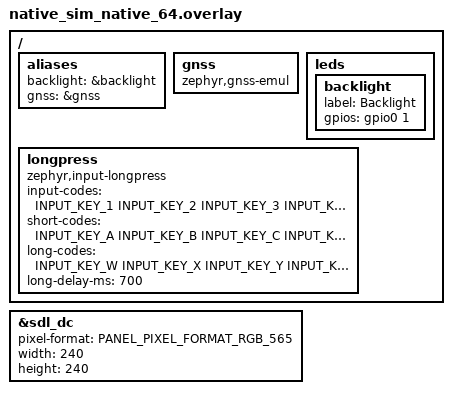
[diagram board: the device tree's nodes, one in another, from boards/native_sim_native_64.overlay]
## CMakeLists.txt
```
cmake_minimum_required(VERSION 3.20.0)

set(BOARD una_watch)
find_package(Zephyr REQUIRED HINTS $ENV{ZEPHYR_BASE})
project(una_zephyr)

target_sources(app PRIVATE
  src/alarm.c
  src/alert.c
  src/baro.c
  src/clock.c
  src/compass.c
  src/compass_page.c
  src/dial.c
  src/draw.c
  src/face.c
  src/fit.c
  src/fonts/font_text_14.c
  src/fonts/font_text_20.c
  src/gnss.c
  src/hr.c
  src/hr_alg.c
  src/hr_page.c
  src/main.c
  src/messages.c
  src/motion.c
  src/pairing.c
  src/phone.c
  src/record.c
  src/record_page.c
  src/screenshot.c
  src/settings.c
  src/stopwatch.c
  src/systems.c
  src/timer.c
  src/totp.c
  src/totp_page.c
  src/ui.c
)

# The hardware, or the simulator's stand-ins for it (-b native_sim/native/64).
if(CONFIG_BOARD_UNA_WATCH)
  target_sources(app PRIVATE
    src/alert_hw.c
    src/baro_hw.c
    src/compass_hw.c
    src/hr_hw.c
    src/motion_hw.c
    src/power.c
    src/storage.c
    src/usb.c
    src/watchdog.c
  )
  # The radio, or in its place what loads the radio chip's firmware
  # (-DEXTRA_CONF_FILE=bnrg-update.conf).
  if(CONFIG_UNA_BNRG_UPDATE)
    get_filename_component(bnrg_fw ${CONFIG_UNA_BNRG_FW} ABSOLUTE BASE_DIR ${CMAKE_SOURCE_DIR})
    if(NOT EXISTS ${bnrg_fw})
      message(FATAL_ERROR "CONFIG_UNA_BNRG_FW: there is no ${bnrg_fw}")
    endif()
    generate_inc_file_for_target(app ${bnrg_fw}
      ${ZEPHYR_BINARY_DIR}/include/generated/bnrg_fw.inc)
    target_sources(app PRIVATE src/bluenrg.c src/bnrg_update.c)
  else()
    target_sources(app PRIVATE src/bluetooth.c)
  endif()
  # PixArt's library on the heart-rate sensor (-DEXTRA_CONF_FILE=hr-ref.conf).
  if(CONFIG_UNA_PIXART_REF)
    get_filename_component(pixart ${CONFIG_UNA_PIXART_DIR} ABSOLUTE BASE_DIR ${CMAKE_SOURCE_DIR})
    if(NOT EXISTS ${pixart}/lib/libuna_vendor.a)
      message(FATAL_ERROR "CONFIG_UNA_PIXART_DIR: there is no ${pixart}/lib/libuna_vendor.a")
    endif()
    target_sources(app PRIVATE src/hr_ref.c)
    target_include_directories(app PRIVATE ${pixart}/include/pixart ${pixart}/include/pixart/alg)
    target_link_libraries(app PRIVATE ${pixart}/lib/libuna_vendor.a)
  endif()
else()
  target_sources(app PRIVATE src/sim.c)
endif()
```

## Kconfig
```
config UNA_BNRG_UPDATE
	bool "Load the radio chip's firmware instead of running the radio"
	depends on BOARD_UNA_WATCH
	help
	  Builds the watch without Bluetooth and with ST's firmware image for
	  the BlueNRG-2N inside, which the shell command "bnrg update" writes
	  into the chip. See bnrg-update.conf.

config UNA_BNRG_FW
	string "ST's firmware image for the radio chip"
	depends on UNA_BNRG_UPDATE
	default "../../../firmware/ble/BlueNRG_2N_FW_V3_4_0.bin"
	help
	  BlueNRG_2N_FW_V3_4_0.bin from fw_images/ in ST's STSW-BNRG2N, by its
	  path from the application's folder or in full.

config UNA_HR_RAW_RECORDED
	bool "Keep the heart-rate sensor's samples of every recording"
	default y
	help
	  While an activity is recorded, what the sensor and the accelerometer
	  gave is written to /USER:/Log/PPG/ as "hr raw on" writes it, about
	  1 MB an hour, for scripts/hr-replay: the pulse while running is not
	  right yet, and this is what there is to work on it with. To be turned
	  off when it is.

config UNA_PIXART_REF
	bool "PixArt's closed library on the heart-rate sensor, with the bus traced"
	depends on BOARD_UNA_WATCH && FPU && FP_HARDABI
	help
	  For working out the PAH8316's registers and for a pulse to hold our
	  own against: the shell command "hrref" runs PixArt's driver and
	  algorithm and writes what they do to /USER:/Log/PPG/. The library is
	  PixArt's and not ours to pass on; it is linked from where
	  UNA_PIXART_DIR says and never copied. See hr-ref.conf.

config UNA_PIXART_DIR
	string "The stock kernel's VendorLib folder"
	depends on UNA_PIXART_REF
	default "../../../refs/una-kernel-public/Software/ThirdParty/VendorLib"
	help
	  The folder with lib/libuna_vendor.a and include/pixart/, by its path
	  from the application's folder or in full.

source "Kconfig.zephyr"
```

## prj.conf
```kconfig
# What the watch and the simulator (native_sim) share. The watch's hardware
# is configured in boards/una_watch.conf, the simulator in
# boards/native_sim_native_64.conf.

CONFIG_GPIO=y
CONFIG_INPUT=y
CONFIG_REBOOT=y
CONFIG_MAIN_STACK_SIZE=8192
# The UI must not be able to starve the shell: a frame is 35 ms of busy work.
CONFIG_MAIN_THREAD_PRIORITY=10
CONFIG_SHELL_THREAD_PRIORITY_OVERRIDE=y
CONFIG_SHELL_THREAD_PRIORITY=5

# Display and UI
CONFIG_DISPLAY=y
CONFIG_LVGL=y
CONFIG_LV_Z_MEM_POOL_SIZE=65536
CONFIG_LV_COLOR_DEPTH_16=y
# One full frame per flush: the panel is always rewritten whole.
CONFIG_LV_Z_VDB_SIZE=100
CONFIG_LV_Z_FULL_REFRESH=y
CONFIG_LV_Z_SHELL=y
CONFIG_LV_FONT_MONTSERRAT_12=y
CONFIG_LV_FONT_MONTSERRAT_14=y
CONFIG_LV_FONT_MONTSERRAT_20=y
CONFIG_LV_FONT_MONTSERRAT_48=y

# Shell
CONFIG_LOG=y
CONFIG_LOG_CMDS=y
CONFIG_SHELL=y
CONFIG_SHELL_PROMPT_UART="una:~$ "
CONFIG_SHELL_VT100_COLORS=n
CONFIG_SHELL_STACK_SIZE=6144
CONFIG_KERNEL_SHELL=y
CONFIG_DEVICE_SHELL=y
CONFIG_GPIO_SHELL=y
CONFIG_INPUT_SHELL=y
CONFIG_THREAD_NAME=y
CONFIG_THREAD_STACK_INFO=y
CONFIG_BASE64=y

CONFIG_RTC=y
CONFIG_RTC_SHELL=y

# Settings in internal flash (storage partition)
CONFIG_FLASH=y
CONFIG_FLASH_MAP=y
CONFIG_SETTINGS=y
CONFIG_SETTINGS_RUNTIME=y
CONFIG_ZMS=y
CONFIG_SETTINGS_ZMS=y

# The recorder: FIT files on the user volume
CONFIG_FILE_SYSTEM=y
CONFIG_CRC=y
```

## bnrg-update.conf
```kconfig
# The watch as a tool that loads the radio chip's firmware: no Bluetooth, and
# the shell commands "bnrg info" and "bnrg update" (src/bnrg_update.c).
#
#   west build -b una_watch --sysbuild -d build/bnrg zephyr/una/app -- \
#     -DEXTRA_CONF_FILE=bnrg-update.conf
#
# The image is ST's (STSW-BNRG2N, fw_images/BlueNRG_2N_FW_V3_4_0.bin in the
# zip) and not ours to pass on, so it is not in the repository. It is looked
# for in firmware/ble/; CONFIG_UNA_BNRG_FW says where else.
CONFIG_BT=n
CONFIG_UNA_BNRG_UPDATE=y
```

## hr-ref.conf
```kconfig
# The watch with PixArt's closed library on the heart-rate sensor, and the
# shell command "hrref" (src/hr_ref.c): what the library does on the bus is
# written to /USER:/Log/PPG/, with the samples and the pulse it makes of them.
#
#   west build -b una_watch --sysbuild -d build/hrref zephyr/una/app -- \
#     -DEXTRA_CONF_FILE=hr-ref.conf
#
# The library is PixArt's, passed on by UNA as a binary, and is not in the
# repository. It is looked for in the stock kernel under refs/;
# CONFIG_UNA_PIXART_DIR says where else.
CONFIG_UNA_PIXART_REF=y
# The library passes floats in the FPU's registers, so all of the watch must.
CONFIG_FPU=y
CONFIG_FP_HARDABI=y
CONFIG_FPU_SHARING=y
# And it wants the mathematics and qsort of a full C library.
CONFIG_NEWLIB_LIBC=y
# That library has an initializer of its own to be run at boot.
CONFIG_STATIC_INIT_GNU=y
```

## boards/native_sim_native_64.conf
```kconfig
# The simulator: the UI and shell as a Linux program. See src/sim.c.

# Works without a GPU and with SDL_VIDEODRIVER=dummy (no window).
CONFIG_SDL_DISPLAY_USE_HARDWARE_ACCELERATOR=n

# The watch has no touch screen. LVGL would poll one 30 times a second.
CONFIG_LV_Z_POINTER_FROM_CHOSEN_TOUCH=n

# The user volume is a directory of the computer: -volume=<dir>:/USER
CONFIG_FILE_SYSTEM_NATIVE_MOUNT=y
CONFIG_FILE_SYSTEM_SHELL=y

# An emulated GNSS receiver, moved about with "sim gps" and "sim move"
CONFIG_GNSS=y
CONFIG_GNSS_SATELLITES=y
CONFIG_GNSS_EMUL_MANUAL_UPDATE=y
CONFIG_PM_DEVICE=y
CONFIG_SHELL_CMD_BUFF_SIZE=3072
```

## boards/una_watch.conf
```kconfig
# The watch itself: its hardware, storage, Bluetooth and firmware update.

CONFIG_HWINFO=y
CONFIG_LOG_BUFFER_SIZE=16384
CONFIG_WATCHDOG=y

# Both serial ports are set up in src/usb.c; the board default does only one.
CONFIG_CDC_ACM_SERIAL_INITIALIZE_AT_BOOT=n

# Shell on the first USB serial port
CONFIG_SHELL_BACKEND_SERIAL_CHECK_DTR=y
CONFIG_HWINFO_SHELL=y
CONFIG_DEVMEM_SHELL=y

# mcumgr on the second USB serial port: upload a new image, test it, reset
CONFIG_STREAM_FLASH=y
CONFIG_IMG_MANAGER=y
CONFIG_ZCBOR=y
CONFIG_NET_BUF=y
CONFIG_CRC=y
CONFIG_MCUMGR=y
CONFIG_UART_MCUMGR=y
CONFIG_MCUMGR_TRANSPORT_UART=y
CONFIG_MCUMGR_GRP_IMG=y
CONFIG_MCUMGR_GRP_OS=y
CONFIG_MCUBOOT_SHELL=y
CONFIG_MCUMGR_GRP_OS_BOOTLOADER_INFO=y
CONFIG_MCUMGR_GRP_OS_INFO=y
CONFIG_UART_INTERRUPT_DRIVEN=y

# Bluetooth: Zephyr's host, with the BlueNRG-2N as a plain controller (ST's
# firmware 3.4.0 or later in it: see bnrg-update.conf). The chip takes ST's
# commands for its address, counts no packets back to the host and knows
# nothing of Zephyr's vendor commands.
CONFIG_SPI=y
CONFIG_BT=y
CONFIG_BT_PERIPHERAL=y
CONFIG_BT_BLUENRG_ACI=y
CONFIG_BT_HCI_ACL_FLOW_CONTROL=n
CONFIG_BT_HCI_VS=n
CONFIG_BT_DEVICE_NAME="UNA Watch"
CONFIG_BT_DEVICE_APPEARANCE=192
# The serial line to the phone: src/bluetooth.c has its own instance of the
# service, for a paired phone only
CONFIG_BT_ZEPHYR_NUS=y
CONFIG_BT_ZEPHYR_NUS_DEFAULT_INSTANCE=n
# Pairing: LE Secure Connections only, by the passkey the watch shows. The
# bonds are kept in settings; a fifth phone takes the place of the oldest.
CONFIG_BT_SMP=y
# No database hash for a phone to keep the services by. With it, Android
# connects, encrypts, and then asks nothing more: Gadgetbridge waits for ever
# (tried again on 23 Nov, with the same phone and bond: stuck with it, well
# without). The price: a paired phone is not told when the services change,
# so the serial service keeps its place (see src/bluetooth.c) and what is
# added after it is found by a phone only when it pairs anew.
CONFIG_BT_GATT_CACHING=n
# Battery level and what the device is, in the standard way, for any app
CONFIG_BT_BAS=y
CONFIG_BT_DIS=y
CONFIG_BT_DIS_MODEL_NUMBER_STR="UNA Watch"
CONFIG_BT_DIS_MANUF_NAME_STR="Una Watch Ltd"
CONFIG_BT_DIS_PNP=n
# The pulse in the standard way too: the sensor is on while an app listens
CONFIG_BT_HRS=y
CONFIG_BT_HCI_ERR_TO_STR=y
CONFIG_BT_SECURITY_ERR_TO_STR=y
CONFIG_BT_SMP_SC_PAIR_ONLY=y
CONFIG_BT_SETTINGS=y
CONFIG_BT_MAX_PAIRED=4
CONFIG_BT_KEYS_OVERWRITE_OLDEST=y
# Its keys are made of the SoC's random numbers (&rng); the host's
# cryptography (PSA) allocates.
CONFIG_ENTROPY_GENERATOR=y
# Pairing was seen to leave the stack's receiving thread 100 bytes of 1200.
CONFIG_BT_RX_STACK_SIZE=2048
CONFIG_COMMON_LIBC_MALLOC_ARENA_SIZE=32768
# As long a packet as the chip carries in one piece
CONFIG_BT_L2CAP_TX_MTU=247
CONFIG_BT_BUF_ACL_TX_SIZE=251
CONFIG_BT_BUF_ACL_RX_SIZE=251
# As many as the chip says it holds
CONFIG_BT_BUF_ACL_TX_COUNT=7
# The pace the watch would like, asked for by src/bluetooth.c once the phone
# has opened the line and not by the stack some seconds into any connection:
# 100 to 200 ms, of which four in five may be skipped, lost after 6 s.
CONFIG_BT_GAP_AUTO_UPDATE_CONN_PARAMS=n
CONFIG_BT_PERIPHERAL_PREF_MIN_INT=80
CONFIG_BT_PERIPHERAL_PREF_MAX_INT=160
CONFIG_BT_PERIPHERAL_PREF_LATENCY=4
CONFIG_BT_PERIPHERAL_PREF_TIMEOUT=600

CONFIG_I2C=y
CONFIG_I2C_SHELL=y
CONFIG_SENSOR=y
CONFIG_PWM=y

# Stop 2 whenever nothing runs and USB is off
CONFIG_PM=y
CONFIG_STATS=y
CONFIG_STATS_NAMES=y
CONFIG_STATS_SHELL=y
CONFIG_PM_STATS=y
CONFIG_GPIO_HOGS=y

# Storage: eMMC, the stock user volume (exFAT) at /USER:
CONFIG_DISK_ACCESS=y
CONFIG_SDMMC_STM32_EMMC=y
CONFIG_FILE_SYSTEM=y
CONFIG_FAT_FILESYSTEM_ELM=y
CONFIG_FS_FATFS_EXFAT=y
CONFIG_FS_FATFS_CUSTOM_MOUNT_POINT_COUNT=1
CONFIG_FS_FATFS_CUSTOM_MOUNT_POINTS="USER"
CONFIG_FS_FATFS_MOUNT_MKFS=n
CONFIG_FILE_SYSTEM_SHELL=y
CONFIG_MCUMGR_GRP_FS=y
CONFIG_MCUMGR_GRP_FS_MAX_FILE_SIZE_4GB=y

# Telemetry: the log, kept on the eMMC by Zephyr's file-system log backend.
# 32 files of 1 MB, oldest overwritten.
CONFIG_LOG_BACKEND_FS=y
# Several threads use the volume (log, shell, mcumgr). Re-entrancy needs the
# long-file-name buffer on the caller's stack, hence the larger stacks.
CONFIG_FS_FATFS_REENTRANT=y
CONFIG_FS_FATFS_LFN_MODE_STACK=y
CONFIG_LOG_PROCESS_THREAD_STACK_SIZE=4096
CONFIG_MCUMGR_TRANSPORT_WORKQUEUE_STACK_SIZE=8192
CONFIG_SYSTEM_WORKQUEUE_STACK_SIZE=4096
CONFIG_LOG_BACKEND_FS_DIR="/USER:/Log/Zephyr"
CONFIG_LOG_BACKEND_FS_FILE_PREFIX="log."
CONFIG_LOG_BACKEND_FS_FILE_SIZE=1048576
CONFIG_LOG_BACKEND_FS_FILES_LIMIT=32
CONFIG_THREAD_RUNTIME_STATS=y
CONFIG_SCHED_THREAD_USAGE=y
CONFIG_SCHED_THREAD_USAGE_ALL=y

# GNSS: the Airoha receiver, off until the recorder asks for it
CONFIG_GNSS=y
CONFIG_GNSS_SATELLITES=y
```

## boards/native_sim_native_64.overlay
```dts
/*
 * The simulator: the watch's 240x240 screen in the SDL display, the
 * backlight on an emulated pin, the same button codes as the watch.
 */

#include <zephyr/dt-bindings/display/panel.h>
#include <zephyr/dt-bindings/input/input-event-codes.h>

/ {
	aliases {
		backlight = &backlight;
		gnss = &gnss;
	};

	gnss: gnss {
		compatible = "zephyr,gnss-emul";
	};

	leds {
		backlight: backlight {
			label = "Backlight";
			gpios = <&gpio0 1 GPIO_ACTIVE_HIGH>;
		};
	};

	/* As in una_watch.dts. There are no buttons: "input report" presses them. */
	longpress {
		compatible = "zephyr,input-longpress";
		input-codes = <INPUT_KEY_1 INPUT_KEY_2 INPUT_KEY_3 INPUT_KEY_4>;
		short-codes = <INPUT_KEY_A INPUT_KEY_B INPUT_KEY_C INPUT_KEY_D>;
		long-codes = <INPUT_KEY_W INPUT_KEY_X INPUT_KEY_Y INPUT_KEY_Z>;
		long-delay-ms = <700>;
	};
};

&sdl_dc {
	pixel-format = <PANEL_PIXEL_FORMAT_RGB_565>;
	width = <240>;
	height = <240>;
};
```

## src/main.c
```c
/*
 * Zephyr on the UNA Watch: the UI in the main thread, a shell on the USB
 * serial port and mcumgr for loading the next build.
 */

#include "ui.h"

int main(void)
{
	ui_run();
	return 0;
}
```

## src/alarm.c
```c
/*
 * One daily alarm.
 */

#include <zephyr/init.h>
#include <zephyr/kernel.h>
#include <zephyr/settings/settings.h>

#include "alarm.h"
#include "alert.h"
#include "clock.h"
#include "ui.h"

#define RING_S 60

static struct {
	uint8_t hour;
	uint8_t minute;
	uint8_t on;
} alarm = {.hour = 7};

bool alarm_get(int *hour, int *minute)
{
	*hour = alarm.hour;
	*minute = alarm.minute;
	return alarm.on;
}

static void check(struct k_work *work);
static K_WORK_DELAYABLE_DEFINE(check_work, check);

/*
 * Looks at the clock at the alarm's minute, and at least once an hour on the
 * way there, so that a wait of many hours does not drift off the RTC.
 */
static void schedule(void)
{
	struct tm now;
	int wait_s = 60;

	if (!alarm.on) {
		k_work_cancel_delayable(&check_work);
		return;
	}
	if (clock_local(&now)) {
		wait_s = (alarm.hour * 60 + alarm.minute - now.tm_hour * 60 - now.tm_min) * 60 -
			 now.tm_sec;
		if (wait_s <= 0) {
			wait_s += 24 * 3600;
		}
	}
	k_work_reschedule(&check_work, K_SECONDS(MIN(wait_s, 3600)));
}

static void check(struct k_work *work)
{
	struct tm now;

	ARG_UNUSED(work);

	if (alarm.on && clock_local(&now) && now.tm_hour == alarm.hour &&
	    now.tm_min == alarm.minute) {
		alert_ring("Alarm", RING_S);
	}
	schedule();
}

void alarm_clock_changed(void)
{
	schedule();
}

static int alarm_setting_set(const char *name, size_t len, settings_read_cb read_cb, void *cb_arg)
{
	if (settings_name_steq(name, "daily", NULL) && len == sizeof(alarm)) {
		return read_cb(cb_arg, &alarm, sizeof(alarm)) < 0 ? -EIO : 0;
	}
	return -ENOENT;
}
SETTINGS_STATIC_HANDLER_DEFINE(alarm, "alarm", NULL, alarm_setting_set, NULL, NULL);

/* After clock_init, which loads the settings. */
static int alarm_init(void)
{
	schedule();
	return 0;
}
SYS_INIT(alarm_init, APPLICATION, 97);

/*
 * The page: SELECT turns the alarm on and off; held, it goes in to set the
 * hour, then the minute.
 */

enum field {
	FIELD_NONE, /* not inside */
	FIELD_HOUR,
	FIELD_MINUTE,
};

static enum field field;
static lv_obj_t *hour_label;
static lv_obj_t *colon_label;
static lv_obj_t *minute_label;
static lv_obj_t *on_label;
static lv_obj_t *hint_label;

static void alarm_enter(void)
{
	ui_title("ALARM");
	hour_label = ui_label(&lv_font_montserrat_48, 0xffffff, -14);
	lv_obj_align(hour_label, LV_ALIGN_CENTER, -40, -14);
	colon_label = ui_label(&lv_font_montserrat_48, 0xffffff, -18);
	lv_label_set_text(colon_label, ":");
	minute_label = ui_label(&lv_font_montserrat_48, 0xffffff, -14);
	lv_obj_align(minute_label, LV_ALIGN_CENTER, 40, -14);
	on_label = ui_label(&lv_font_montserrat_20, 0xffffff, 32);
	hint_label = ui_label(&lv_font_montserrat_14, 0xaaaaaa, 72);
	field = FIELD_NONE;
}

static uint32_t alarm_update(void)
{
	/* An alarm that is off is grey; the field being set is cyan. */
	const lv_color_t plain = lv_color_hex(alarm.on ? 0xffffff : 0x555555);
	const lv_color_t chosen = lv_color_hex(0x00ffff);

	lv_label_set_text_fmt(hour_label, "%02d", alarm.hour);
	lv_label_set_text_fmt(minute_label, "%02d", alarm.minute);
	lv_label_set_text(on_label, alarm.on ? "ON" : "OFF");
	lv_obj_set_style_text_color(on_label, lv_color_hex(alarm.on ? 0x00ff00 : 0x555555), 0);
	lv_obj_set_style_text_color(colon_label, plain, 0);
	lv_obj_set_style_text_color(hour_label, field == FIELD_HOUR ? chosen : plain, 0);
	lv_obj_set_style_text_color(minute_label, field == FIELD_MINUTE ? chosen : plain, 0);
	lv_label_set_text(hint_label, field == FIELD_NONE ? "hold: set" : "");
	return UINT32_MAX;
}

static bool alarm_key(enum ui_key key, bool held)
{
	int dir = key == UI_KEY_UP ? 1 : -1;

	if (field == FIELD_NONE) {
		if (key != UI_KEY_SELECT) {
			return false;
		}
		if (held) {
			field = FIELD_HOUR;
			return true;
		}
		alarm.on = !alarm.on;
	} else if (key == UI_KEY_SELECT || key == UI_KEY_BACK) {
		if (!held) {
			field = key == UI_KEY_SELECT && field == FIELD_HOUR ? FIELD_MINUTE
									     : FIELD_NONE;
		}
		return true;
	} else if (field == FIELD_HOUR) {
		alarm.hour = (alarm.hour + 24 + dir) % 24;
	} else if (held) {
		/* Fives, to the next multiple; held: single minutes. */
		alarm.minute = (alarm.minute + 60 + dir) % 60;
	} else if (dir > 0) {
		alarm.minute = (alarm.minute / 5 * 5 + 5) % 60;
	} else {
		alarm.minute = ((alarm.minute + 4) / 5 * 5 + 55) % 60;
	}
	settings_save_one("alarm/daily", &alarm, sizeof(alarm));
	schedule();
	return true;
}

const struct ui_screen alarm_screen = {
	.name = "alarm",
	.enter = alarm_enter,
	.update = alarm_update,
	.key = alarm_key,
};
```

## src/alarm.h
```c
#ifndef UNA_ALARM_H_
#define UNA_ALARM_H_

#include <stdbool.h>

/* The daily alarm's time; false when it is off. */
bool alarm_get(int *hour, int *minute);

/* The clock was set: work out again when the alarm is due. */
void alarm_clock_changed(void);

#endif
```

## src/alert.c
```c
/*
 * Alerts: a beep-and-buzz pattern, and the screen shown while it plays.
 */

#include <stdlib.h>

#include <zephyr/kernel.h>
#include <zephyr/logging/log.h>
#include <zephyr/settings/settings.h>
#include <zephyr/shell/shell.h>

#include "alert.h"
#include "clock.h"
#include "ui.h"

LOG_MODULE_REGISTER(alert, LOG_LEVEL_INF);

/* Two short pulses a second. */
static const struct {
	uint16_t ms;
	bool on;
} pattern[] = {{150, true}, {100, false}, {150, true}, {600, false}};

#define PATTERN_MS 1000

static uint8_t sound = 1;
static uint8_t vibration = 1;

/*
 * A pattern is asked for from any thread and played by the work alone: the
 * steps to play from the beginning, 0 to stop, -1 when nothing is asked.
 * Cancelling the work instead would, if it is running just then, have the
 * kernel refuse every schedule until it returns, its own for the next step
 * among them, and whatever was on would stay on.
 */
static atomic_t asked = ATOMIC_INIT(-1);

/* The work's own: steps still to play, the one that is next, and when. */
static int steps_left;
static int step;
static int64_t step_at;

static void play_step(struct k_work *work);
static K_WORK_DELAYABLE_DEFINE(step_work, play_step);

static void play_step(struct k_work *work)
{
	int fresh = atomic_set(&asked, -1);
	int64_t now = k_uptime_get();
	bool on;

	if (fresh >= 0) {
		steps_left = fresh;
		step = 0;
	} else if (steps_left > 0 && now < step_at) {
		/* Woken for a pattern that an earlier run already took. */
		k_work_schedule(&step_work, K_MSEC(step_at - now));
		return;
	}
	if (steps_left <= 0) {
		buzzer_set(false);
		motor_set(false);
		return;
	}
	steps_left--;
	on = pattern[step].on;
	buzzer_set(on && sound);
	motor_set(on && vibration);
	step_at = k_uptime_get() + pattern[step].ms;
	k_work_schedule(&step_work, K_MSEC(pattern[step].ms));
	step = (step + 1) % ARRAY_SIZE(pattern);
}

/* Whether what was last asked for is the ring that the ring screen shows. */
static atomic_t ringing;

static void start(int steps)
{
	atomic_set(&ringing, 0);
	atomic_set(&asked, steps);
	k_work_reschedule(&step_work, K_NO_WAIT);
}

void alert_stop(void)
{
	start(0);
}

void alert_blip(void)
{
	start(2);
}

/* The screen */

static const char *ring_title;
static char ring_time[6];

static void ring_enter(void)
{
	lv_label_set_text(ui_label(&lv_font_montserrat_48, 0xffffff, -20), ring_time);
	lv_label_set_text(ui_label(&font_text_20, 0xffff00, 30), ring_title);
	lv_label_set_text(ui_label(&lv_font_montserrat_14, 0xaaaaaa, 76), "any button: dismiss");
}

static uint32_t ring_update(void)
{
	return UINT32_MAX;
}

static bool ring_key(enum ui_key key, bool held)
{
	ARG_UNUSED(key);
	ARG_UNUSED(held);

	ui_pop();
	return true;
}

/*
 * Leaving is what silences it, so that holding BACK, which the screen does
 * not see, does too. A blip that has come since is left alone.
 */
static void ring_leave(void)
{
	if (atomic_get(&ringing)) {
		alert_stop();
	}
}

static const struct ui_screen ring_screen = {
	.name = "ring",
	.enter = ring_enter,
	.update = ring_update,
	.key = ring_key,
	.leave = ring_leave,
};

void alert_ring(const char *title, int seconds)
{
	struct tm now;

	LOG_INF("ring: %s", title);
	ring_title = title;
	if (clock_local(&now)) {
		snprintk(ring_time, sizeof(ring_time), "%02d:%02d", now.tm_hour, now.tm_min);
	} else {
		ring_time[0] = '\0';
	}
	start(seconds * 1000 / PATTERN_MS * ARRAY_SIZE(pattern));
	atomic_set(&ringing, 1);
	ui_show(&ring_screen);
}

/* Settings */

bool alert_sound(void)
{
	return sound;
}

void alert_set_sound(bool on)
{
	sound = on;
	settings_save_one("alert/sound", &sound, sizeof(sound));
}

bool alert_vibration(void)
{
	return vibration;
}

void alert_set_vibration(bool on)
{
	vibration = on;
	settings_save_one("alert/vibration", &vibration, sizeof(vibration));
}

static int alert_setting_set(const char *name, size_t len, settings_read_cb read_cb, void *cb_arg)
{
	uint8_t *value = settings_name_steq(name, "sound", NULL)       ? &sound
			 : settings_name_steq(name, "vibration", NULL) ? &vibration
								       : NULL;

	if (value == NULL || len != sizeof(*value)) {
		return -ENOENT;
	}
	return read_cb(cb_arg, value, sizeof(*value)) < 0 ? -EIO : 0;
}
SETTINGS_STATIC_HANDLER_DEFINE(alert, "alert", NULL, alert_setting_set, NULL, NULL);

/* alert ring [seconds] | alert stop */
static int cmd_ring(const struct shell *sh, size_t argc, char **argv)
{
	alert_ring("Test", argc > 1 ? atoi(argv[1]) : 5);
	return 0;
}

static int cmd_stop(const struct shell *sh, size_t argc, char **argv)
{
	alert_stop();
	return 0;
}

SHELL_STATIC_SUBCMD_SET_CREATE(alert_cmds,
	SHELL_CMD_ARG(ring, NULL, "Ring for [seconds] (default 5)", cmd_ring, 1, 1),
	SHELL_CMD(stop, NULL, "Silence", cmd_stop),
	SHELL_SUBCMD_SET_END);
SHELL_CMD_REGISTER(alert, &alert_cmds, "Beep and vibrate", NULL);
```

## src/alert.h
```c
#ifndef UNA_ALERT_H_
#define UNA_ALERT_H_

#include <stdbool.h>

/*
 * Beep and vibrate for up to `seconds`, and show `title` until a button is
 * pressed, which also ends the noise. From any thread.
 */
void alert_ring(const char *title, int seconds);
void alert_stop(void);

/* One short beep and buzz. */
void alert_blip(void);

/* What an alert may use. Stored. */
bool alert_sound(void);
void alert_set_sound(bool on);
bool alert_vibration(void);
void alert_set_vibration(bool on);

/* The hardware: src/alert_hw.c on the watch, src/sim.c in the simulator. */
void buzzer_set(bool on);
void motor_set(bool on);

#endif
```

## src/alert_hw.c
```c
/*
 * The buzzer and the vibration motor.
 *
 * Buzzer: a piezo on TIM4 channel 3 behind two enable pins that set its
 * level, as in Components/Buzzer.cpp of una-kernel-public. Motor: an ERM on a
 * DRV2625, driven open-loop in real-time mode, which needs none of the
 * calibration the stock firmware runs; the chip is in shutdown otherwise.
 */

#include <zephyr/device.h>
#include <zephyr/drivers/gpio.h>
#include <zephyr/drivers/i2c.h>
#include <zephyr/drivers/pwm.h>
#include <zephyr/init.h>
#include <zephyr/kernel.h>
#include <zephyr/logging/log.h>
#include <zephyr/pm/policy.h>

#include "alert.h"

LOG_MODULE_REGISTER(alert_hw, LOG_LEVEL_INF);

#define USER DT_PATH(zephyr_user)

static const struct pwm_dt_spec buzzer = PWM_DT_SPEC_GET(USER);
static const struct gpio_dt_spec buzzer_en1 = GPIO_DT_SPEC_GET_BY_IDX(USER, buzzer_en_gpios, 0);
static const struct gpio_dt_spec buzzer_en2 = GPIO_DT_SPEC_GET_BY_IDX(USER, buzzer_en_gpios, 1);
static const struct gpio_dt_spec motor_en = GPIO_DT_SPEC_GET(USER, haptic_enable_gpios);
static const struct device *const i2c = DEVICE_DT_GET(DT_NODELABEL(i2c1));

#define DRV2625_ADDR 0x5a

#define DRV2625_MODE      0x07 /* [1:0] mode, 0 = real-time; [3:2] trigger pin */
#define DRV2625_LOOP      0x08
#define DRV2625_GO        0x0c
#define DRV2625_RTP_INPUT 0x0e
#define DRV2625_OD_CLAMP  0x20

/* ERM, open loop, brake into standby when stopped. */
#define DRV2625_LOOP_ERM_OPEN (BIT(6) | BIT(3))
/* 2.95 V, the stock firmware's limit for this motor. */
#define DRV2625_OD_CLAMP_2V95 137

void buzzer_set(bool on)
{
	static bool is_on;

	if (on == is_on) {
		return;
	}
	is_on = on;
	if (on) {
		/* The timer stands still in Stop mode. */
		pm_policy_state_lock_get(PM_STATE_SUSPEND_TO_IDLE, PM_ALL_SUBSTATES);
		/* Both enables: the loudest of the three levels. */
		gpio_pin_set_dt(&buzzer_en1, 1);
		gpio_pin_set_dt(&buzzer_en2, 1);
		pwm_set_pulse_dt(&buzzer, buzzer.period / 2);
	} else {
		pwm_set_pulse_dt(&buzzer, 0);
		gpio_pin_set_dt(&buzzer_en1, 0);
		gpio_pin_set_dt(&buzzer_en2, 0);
		pm_policy_state_lock_put(PM_STATE_SUSPEND_TO_IDLE, PM_ALL_SUBSTATES);
	}
}

void motor_set(bool on)
{
	static bool is_on;
	int err;

	if (on == is_on) {
		return;
	}
	is_on = on;
	if (!on) {
		i2c_reg_write_byte(i2c, DRV2625_ADDR, DRV2625_GO, 0);
		gpio_pin_set_dt(&motor_en, 0);
		return;
	}
	/* Out of shutdown the registers are at their defaults. */
	gpio_pin_set_dt(&motor_en, 1);
	k_msleep(2);
	err = i2c_reg_write_byte(i2c, DRV2625_ADDR, DRV2625_LOOP, DRV2625_LOOP_ERM_OPEN);
	if (err == 0) {
		err = i2c_reg_write_byte(i2c, DRV2625_ADDR, DRV2625_OD_CLAMP,
					 DRV2625_OD_CLAMP_2V95);
	}
	if (err == 0) {
		err = i2c_reg_update_byte(i2c, DRV2625_ADDR, DRV2625_MODE, 0x0f, 0);
	}
	if (err == 0) {
		err = i2c_reg_write_byte(i2c, DRV2625_ADDR, DRV2625_RTP_INPUT, 0x7f);
	}
	if (err == 0) {
		err = i2c_reg_write_byte(i2c, DRV2625_ADDR, DRV2625_GO, 1);
	}
	if (err != 0) {
		LOG_ERR("motor driver: %d", err);
	}
}

static int alert_hw_init(void)
{
	gpio_pin_configure_dt(&buzzer_en1, GPIO_OUTPUT_INACTIVE);
	gpio_pin_configure_dt(&buzzer_en2, GPIO_OUTPUT_INACTIVE);
	gpio_pin_configure_dt(&motor_en, GPIO_OUTPUT_INACTIVE);
	return 0;
}
SYS_INIT(alert_hw_init, APPLICATION, CONFIG_APPLICATION_INIT_PRIORITY);
```

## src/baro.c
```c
/*
 * The barometer, for height gained and lost: powered while anyone wants it,
 * read once a second, the readings evened out.
 */

#include <errno.h>
#include <stdlib.h>
#include <string.h>

#include <zephyr/kernel.h>
#include <zephyr/logging/log.h>
#include <zephyr/shell/shell.h>
#include <zephyr/sys/atomic.h>

#include "baro.h"
#include "ui.h"

LOG_MODULE_REGISTER(baro, LOG_LEVEL_INF);

#define PERIOD_MS 1000
/* A reading older than this is not where the watch is now. */
#define FRESH_MS  3000
/*
 * Each reading moves the height a quarter of the way: a wrist swung and a
 * gust are gone in it, a stair climbed shows within a few seconds.
 */
#define SMOOTH    4
/* So many readings failed in a row: the supply is taken away and given back. */
#define FAILURES_TO_RESTART 5

static atomic_t wanted;
static K_SEM_DEFINE(wake, 0, 1);

static struct k_spinlock lock;
static struct baro_reading last;
static bool have_last;
static struct baro_status state;

void baro_want(enum baro_user user, bool on)
{
	if (on) {
		atomic_set_bit(&wanted, user);
	} else {
		atomic_clear_bit(&wanted, user);
	}
	k_sem_give(&wake);
}

bool baro_wanted(enum baro_user user)
{
	return atomic_test_bit(&wanted, user);
}

bool baro_read(struct baro_reading *reading)
{
	bool fresh;

	K_SPINLOCK(&lock) {
		*reading = last;
		fresh = have_last && k_uptime_get() - last.at_ms < FRESH_MS;
	}
	return fresh;
}

void baro_status(struct baro_status *status)
{
	K_SPINLOCK(&lock) {
		*status = state;
	}
}

/*
 * The standard atmosphere: 1013.25 hPa at the sea, and from there
 * 44330.77 m * (1 - (p / p0) ^ 0.190263). The C library here has no
 * mathematics; the power is made of a logarithm and an exponential, both
 * from their series, which are short over the pressures there are.
 */
static int32_t altitude_of(int32_t pressure_pa)
{
	double x = pressure_pa / 101325.0;
	double z = (x - 1) / (x + 1), z2 = z * z;
	double term = z, ln = 0, y, power = 1;

	for (int n = 1; n < 40; n += 2) {
		ln += term / n;
		term *= z2;
	}
	y = 0.190263 * 2 * ln;
	term = 1;
	for (int n = 1; n < 16; n++) {
		term *= y / n;
		power += term;
	}
	return (int32_t)(44330770.0 * (1.0 - power));
}

static bool set_power(bool on)
{
	int ret = baro_hw_power(on);

	K_SPINLOCK(&lock) {
		state.on = on && ret == 0;
		state.readings = 0;
		have_last = false;
		if (on) {
			state.present = ret == 0;
		}
	}
	if (on && ret != 0) {
		LOG_ERR("no sensor: %d", ret);
		(void)baro_hw_power(false);
		/* Whoever wanted it must ask again. */
		atomic_clear(&wanted);
	} else {
		LOG_INF("sensor %s (wanted by %lx)", on ? "on" : "off", (long)atomic_get(&wanted));
	}
	ui_refresh();
	return on && ret == 0;
}

static void sample(void)
{
	static int in_a_row;
	int32_t pressure_pa, temperature_cc, altitude_mm;
	int ret = baro_hw_sample(&pressure_pa, &temperature_cc);

	/* Outside what the sensor measures is no reading either. */
	if (ret == 0 && (pressure_pa < 30000 || pressure_pa > 120000)) {
		ret = -ERANGE;
	}
	if (ret != 0) {
		K_SPINLOCK(&lock) {
			state.failures++;
		}
		if (++in_a_row == FAILURES_TO_RESTART) {
			LOG_WRN("reading fails (%d): supply off and on", ret);
			in_a_row = 0;
			(void)baro_hw_power(false);
			k_msleep(20);
			if (!set_power(true)) {
				return;
			}
		}
		return;
	}
	in_a_row = 0;
	altitude_mm = altitude_of(pressure_pa);
	K_SPINLOCK(&lock) {
		if (have_last) {
			altitude_mm = last.altitude_mm + (altitude_mm - last.altitude_mm) / SMOOTH;
		}
		last = (struct baro_reading){
			.pressure_pa = pressure_pa,
			.temperature_cc = temperature_cc,
			.altitude_mm = altitude_mm,
			.at_ms = k_uptime_get(),
		};
		have_last = true;
		state.readings++;
	}
}

static void baro_thread(void *p1, void *p2, void *p3)
{
	bool on = false;
	int64_t next_ms = 0;

	(void)baro_hw_power(false);
	while (true) {
		bool want = atomic_get(&wanted) != 0;

		if (want != on) {
			on = set_power(want);
			next_ms = k_uptime_get();
		}
		if (!on) {
			k_sem_take(&wake, K_FOREVER);
			continue;
		}
		if (k_uptime_get() >= next_ms) {
			sample();
			on = state.on;
			next_ms += PERIOD_MS;
			if (next_ms < k_uptime_get()) {
				next_ms = k_uptime_get() + PERIOD_MS;
			}
		}
		k_sem_take(&wake, K_TIMEOUT_ABS_MS(next_ms));
	}
}
K_THREAD_DEFINE(baro_tid, 2048, baro_thread, NULL, NULL, NULL, 9, 0, 500);

/* baro [on|off] */
static int cmd_baro(const struct shell *sh, size_t argc, char **argv)
{
	struct baro_reading r;
	struct baro_status s;

	if (argc > 1) {
		baro_want(BARO_FOR_SHELL, strcmp(argv[1], "on") == 0);
		return 0;
	}
	baro_status(&s);
	shell_print(sh, "%s, %s, %u readings, %u failures",
		    s.present ? "present" : "not seen", s.on ? "on" : "off", s.readings,
		    s.failures);
	if (baro_read(&r)) {
		shell_print(sh, "%d Pa, %d.%02d C, %d mm in the standard atmosphere",
			    (int)r.pressure_pa, (int)(r.temperature_cc / 100),
			    abs((int)(r.temperature_cc % 100)), (int)r.altitude_mm);
	}
	return 0;
}
SHELL_CMD_ARG_REGISTER(baro, NULL, "Barometer state, or turn it on or off: baro [on|off]",
		       cmd_baro, 1, 1);
```

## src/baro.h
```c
#ifndef UNA_BARO_H_
#define UNA_BARO_H_

#include <stdbool.h>
#include <stdint.h>

/*
 * The barometer: on while anyone wants it, read once a second.
 */

/* Who may want it on. */
enum baro_user {
	BARO_FOR_RECORD,
	BARO_FOR_PAGE,
	BARO_FOR_SHELL,
};

/* Returns at once; the first reading is there within a second or two. */
void baro_want(enum baro_user user, bool on);
bool baro_wanted(enum baro_user user);

struct baro_reading {
	int32_t pressure_pa;
	int32_t temperature_cc; /* hundredths of a degree, of the sensor itself */
	/*
	 * What the pressure is as a height in the standard atmosphere, evened
	 * out over a few seconds. Good for differences; as a height above the
	 * sea it is off by what the weather is, a hundred metres and more.
	 */
	int32_t altitude_mm;
	int64_t at_ms; /* uptime */
};

/* False when there is none, or none fresh enough to use. */
bool baro_read(struct baro_reading *reading);

struct baro_status {
	bool present; /* there is a sensor; known once it has been on */
	bool on;
	uint32_t readings; /* since it was turned on */
	uint32_t failures; /* since boot */
};

void baro_status(struct baro_status *status);

/*
 * The sensor itself: src/baro_hw.c, or the simulator's stand-in. Pressure
 * in Pa, temperature in hundredths of a degree.
 */
int baro_hw_power(bool on);
int baro_hw_sample(int32_t *pressure_pa, int32_t *temperature_cc);

#endif
```

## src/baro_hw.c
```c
/*
 * MS5837-02BA on I2C2, its supply switched by a pin.
 *
 * The sensor is asked to convert, pressure and then temperature, and each
 * is read when the conversion is over. What comes out is raw: the sensor
 * carries the figures of its own calibration, read once after power-on, and
 * the datasheet gives the arithmetic that makes Pa and degrees of them.
 *
 * Zephyr has a driver for the part. It is not used: it reads the calibration
 * at boot, when this one has no supply, and without the pause the sensor
 * needs after a reset or a check of what was read.
 */

#include <errno.h>
#include <string.h>

#include <zephyr/devicetree.h>
#include <zephyr/drivers/gpio.h>
#include <zephyr/drivers/i2c.h>
#include <zephyr/kernel.h>
#include <zephyr/logging/log.h>
#include <zephyr/sys/byteorder.h>

#include "baro.h"

LOG_MODULE_REGISTER(baro_hw, LOG_LEVEL_INF);

static const struct device *const bus = DEVICE_DT_GET(DT_NODELABEL(i2c2));
static const struct gpio_dt_spec enable = GPIO_DT_SPEC_GET(DT_PATH(zephyr_user), baro_en_gpios);

#define ADDRESS 0x76

#define CMD_RESET       0x1e
#define CMD_READ        0x00
#define CMD_PRESSURE    0x4a /* 8192 samples to a reading: the least noise */
#define CMD_TEMPERATURE 0x54 /* 1024 */
#define CMD_PROM        0xa0

/* As the stock firmware waits; the datasheet's figures are below these. */
#define POWER_OFF_MS       20
#define POWER_ON_MS        10
#define RESET_MS           10
#define PRESSURE_MS        20
#define TEMPERATURE_MS     3
#define ATTEMPTS           3

#define PROM_WORDS 7

static uint16_t prom[PROM_WORDS];

/* The checksum over the calibration, four bits of its first word. */
static uint8_t crc4(const uint16_t *words)
{
	uint16_t w[8];
	uint16_t rem = 0;

	memcpy(w, words, PROM_WORDS * sizeof(uint16_t));
	w[0] &= 0x0fff;
	w[7] = 0;
	for (int i = 0; i < 16; i++) {
		rem ^= i % 2 == 1 ? w[i / 2] & 0xff : w[i / 2] >> 8;
		for (int bit = 0; bit < 8; bit++) {
			rem = rem & 0x8000 ? (rem << 1) ^ 0x3000 : rem << 1;
		}
	}
	return rem >> 12;
}

static int start(void)
{
	uint8_t cmd = CMD_RESET;
	bool blank = true;
	int ret;

	ret = i2c_write(bus, &cmd, 1, ADDRESS);
	if (ret != 0) {
		return ret;
	}
	k_msleep(RESET_MS);
	for (int i = 0; i < PROM_WORDS; i++) {
		uint8_t raw[2];

		ret = i2c_burst_read(bus, ADDRESS, CMD_PROM + 2 * i, raw, sizeof(raw));
		if (ret != 0) {
			return ret;
		}
		prom[i] = sys_get_be16(raw);
		blank = blank && (prom[i] == 0 || prom[i] == 0xffff);
	}
	/* All zeros pass the checksum and are no calibration. */
	if (blank || crc4(prom) != prom[0] >> 12) {
		return -EBADMSG;
	}
	return 0;
}

int baro_hw_power(bool on)
{
	static bool told;
	int ret = -ENODEV;

	if (!device_is_ready(bus) || !gpio_is_ready_dt(&enable)) {
		return -ENODEV;
	}
	/* Off first, whatever it was: a sensor that is stuck needs it. */
	gpio_pin_configure_dt(&enable, GPIO_OUTPUT_INACTIVE);
	if (!on) {
		return 0;
	}
	for (int attempt = 0; attempt < ATTEMPTS && ret != 0; attempt++) {
		gpio_pin_set_dt(&enable, 0);
		k_msleep(POWER_OFF_MS);
		gpio_pin_set_dt(&enable, 1);
		k_msleep(POWER_ON_MS);
		ret = start();
	}
	if (ret == 0 && !told) {
		told = true;
		/* 0 is the 02BA01, which the arithmetic below is for. */
		LOG_INF("MS5837, version code 0x%02x, calibration %u %u %u %u %u %u",
			(prom[0] >> 5) & 0x7f, prom[1], prom[2], prom[3], prom[4], prom[5],
			prom[6]);
	}
	return ret;
}

static int convert(uint8_t cmd, int wait_ms, uint32_t *raw)
{
	uint8_t bytes[3];
	int ret;

	ret = i2c_write(bus, &cmd, 1, ADDRESS);
	if (ret != 0) {
		return ret;
	}
	k_msleep(wait_ms);
	ret = i2c_burst_read(bus, ADDRESS, CMD_READ, bytes, sizeof(bytes));
	*raw = sys_get_be24(bytes);
	/* A conversion not over reads as nothing. */
	return ret != 0 ? ret : *raw == 0 ? -EAGAIN : 0;
}

int baro_hw_sample(int32_t *pressure_pa, int32_t *temperature_cc)
{
	uint32_t d1, d2;
	int64_t dt, off, sens, temp;
	int ret;

	ret = convert(CMD_PRESSURE, PRESSURE_MS, &d1);
	if (ret == 0) {
		ret = convert(CMD_TEMPERATURE, TEMPERATURE_MS, &d2);
	}
	if (ret != 0) {
		return ret;
	}
	/* The datasheet's, for the 02BA: first order, then the correction in the cold. */
	dt = (int64_t)d2 - ((int64_t)prom[5] << 8);
	temp = 2000 + dt * prom[6] / (1LL << 23);
	off = ((int64_t)prom[2] << 17) + dt * prom[4] / (1LL << 6);
	sens = ((int64_t)prom[1] << 16) + dt * prom[3] / (1LL << 7);
	if (temp < 2000) {
		int64_t below = (temp - 2000) * (temp - 2000);

		temp -= 11 * dt * dt / (1LL << 35);
		off -= 31 * below / (1LL << 3);
		sens -= 63 * below / (1LL << 5);
	}
	/* In hundredths of a millibar, which are Pa. */
	*pressure_pa = (int32_t)((sens * d1 / (1LL << 21) - off) / (1LL << 15));
	*temperature_cc = (int32_t)temp;
	return 0;
}
```

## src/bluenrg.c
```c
/*
 * BlueNRG-2N over SPI.
 *
 * The chip raises its IRQ line when it has something to be read. Every
 * transfer starts with five bytes each way: ours say read or write, the
 * chip's how many bytes it has for us and how many it can take. A sleeping
 * chip wakes on chip select and raises IRQ when it is ready for the five.
 *
 * One thread reads. An answer to a command goes to whoever waits in
 * bluenrg_cmd(), everything else into a queue for bluenrg_event().
 */

#include <string.h>

#include <zephyr/drivers/gpio.h>
#include <zephyr/drivers/spi.h>
#include <zephyr/kernel.h>
#include <zephyr/logging/log.h>
#include <zephyr/sys/byteorder.h>
#include <zephyr/sys/util.h>

#include "bluenrg.h"

LOG_MODULE_REGISTER(bluenrg, LOG_LEVEL_INF);

#define NODE DT_NODELABEL(hci_spi)

static const struct spi_dt_spec bus =
	SPI_DT_SPEC_GET(NODE, SPI_OP_MODE_CONTROLLER | SPI_TRANSFER_MSB | SPI_WORD_SET(8) |
				      SPI_LOCK_ON);
static const struct gpio_dt_spec irq = GPIO_DT_SPEC_GET(NODE, irq_gpios);
static const struct gpio_dt_spec reset = GPIO_DT_SPEC_GET(NODE, reset_gpios);

#define SPI_WRITE 0x0a
#define SPI_READ  0x0b

#define PACKET_COMMAND   0x01
#define PACKET_EVENT     0x04
#define PACKET_EVENT_EXT 0x82 /* ST's: an event with a two-byte length */

#define EVENT_COMMAND_COMPLETE 0x0e
#define EVENT_COMMAND_STATUS   0x0f
#define VENDOR_INITIALIZED     0x0001
/* Its buffers are full for now: the caller tries again. */
#define STATUS_NO_BUFFERS      0x64

#define RESET_MS   10
/* Firmware 3.4.0 checks its own image before it starts: about two seconds. */
#define START_MS   5000
#define ANSWER_MS  2000
#define PACKET_MAX 520

static K_MUTEX_DEFINE(bus_lock);
static K_MUTEX_DEFINE(cmd_lock);
static K_SEM_DEFINE(irq_raised, 0, 1);
static K_SEM_DEFINE(started, 0, 1);
static K_SEM_DEFINE(answered, 0, 1);
K_MSGQ_DEFINE(bluenrg_events, sizeof(struct bluenrg_event), 6, 4);

static struct gpio_callback irq_callback;
static bool running, starting;
static uint8_t start_reason;

/* The command being waited for, and its answer. */
static struct k_spinlock pending_lock;
static uint16_t pending_opcode;
static bool pending;
static uint8_t answer[PACKET_MAX];
static size_t answer_len;

static void on_irq(const struct device *port, struct gpio_callback *cb, uint32_t pins)
{
	ARG_UNUSED(port);
	ARG_UNUSED(cb);
	ARG_UNUSED(pins);

	k_sem_give(&irq_raised);
}

static int transfer(const uint8_t *tx, uint8_t *rx, size_t len)
{
	const struct spi_buf tx_buf = {.buf = (void *)tx, .len = len};
	const struct spi_buf rx_buf = {.buf = rx, .len = len};
	const struct spi_buf_set tx_set = {.buffers = &tx_buf, .count = 1};
	const struct spi_buf_set rx_set = {.buffers = &rx_buf, .count = 1};

	return spi_transceive_dt(&bus, tx != NULL ? &tx_set : NULL, rx != NULL ? &rx_set : NULL);
}

/*
 * Select the chip, wait until it is ready and exchange the five bytes.
 * The bus stays ours, with the chip selected, until deselect().
 */
static int select(uint8_t op, uint16_t *to_read, uint16_t *to_write)
{
	uint8_t ours[5] = {op, 0, 0, 0, 0};
	uint8_t theirs[5];
	int ret;

	/* Nothing goes over the bus: this takes it and lowers chip select. */
	ret = transfer(ours, NULL, 0);
	if (ret != 0) {
		return ret;
	}
	if (!WAIT_FOR(gpio_pin_get_dt(&irq) > 0, 100000, k_usleep(100))) {
		return -ETIMEDOUT;
	}
	ret = transfer(ours, theirs, sizeof(ours));
	*to_write = sys_get_le16(&theirs[1]);
	*to_read = sys_get_le16(&theirs[3]);
	return ret;
}

static void deselect(bool wait_low)
{
	spi_release_dt(&bus);
	if (wait_low) {
		/* The chip lowers IRQ once it has seen the end of the transfer. */
		WAIT_FOR(gpio_pin_get_dt(&irq) == 0, 10000, k_usleep(50));
	}
}

/* One packet from the chip, if it has one. Returns its length. */
static int read_packet(uint8_t *packet, size_t size)
{
	uint16_t to_read = 0, to_write;
	int ret;

	k_mutex_lock(&bus_lock, K_FOREVER);
	if (gpio_pin_get_dt(&irq) <= 0) {
		k_mutex_unlock(&bus_lock);
		return 0;
	}
	ret = select(SPI_READ, &to_read, &to_write);
	if (ret == 0 && to_read > size) {
		LOG_ERR("packet of %u bytes", to_read);
		ret = -EMSGSIZE;
	}
	if (ret == 0 && to_read > 0) {
		/* What goes out meanwhile is all ones, as ST's own code sends. */
		static uint8_t ones[PACKET_MAX];

		memset(ones, 0xff, to_read);
		ret = transfer(ones, packet, to_read);
	}
	deselect(ret == 0 && to_read > 0);
	k_mutex_unlock(&bus_lock);
	return ret < 0 ? ret : to_read;
}

static int write_packet(const uint8_t *packet, size_t len)
{
	uint16_t to_read, to_write = 0;
	int ret;

	k_mutex_lock(&bus_lock, K_FOREVER);
	/* The chip wants a pause after the transfer before. */
	k_usleep(100);
	ret = select(SPI_WRITE, &to_read, &to_write);
	if (ret == 0 && to_write < len) {
		ret = -ENOBUFS;
	}
	if (ret == 0) {
		ret = transfer(packet, NULL, len);
	}
	deselect(ret == 0);
	k_mutex_unlock(&bus_lock);
	return ret;
}

/* An answer is a command-complete or command-status event with our opcode. */
static bool take_answer(const uint8_t *packet, size_t len)
{
	uint16_t opcode;
	bool taken = false;

	if (packet[0] != PACKET_EVENT || len < 6) {
		return false;
	}
	if (packet[1] == EVENT_COMMAND_COMPLETE) {
		opcode = sys_get_le16(&packet[4]);
	} else if (packet[1] == EVENT_COMMAND_STATUS && len >= 7) {
		opcode = sys_get_le16(&packet[5]);
	} else {
		return false;
	}
	K_SPINLOCK(&pending_lock) {
		if (pending && opcode == pending_opcode) {
			if (packet[1] == EVENT_COMMAND_COMPLETE) {
				answer_len = len - 6;
				memcpy(answer, &packet[6], answer_len);
			} else {
				answer_len = 1;
				answer[0] = packet[3];
			}
			pending = false;
			taken = true;
		}
	}
	if (taken) {
		k_sem_give(&answered);
	}
	/* An answer nobody waits for is nothing to anyone else either. */
	return true;
}

static void queue_event(const uint8_t *packet, size_t len)
{
	static struct bluenrg_event ev;
	const uint8_t *body;
	size_t body_len;

	if (packet[0] == PACKET_EVENT && len >= 3) {
		body = &packet[3];
		body_len = MIN(packet[2], len - 3);
	} else if (packet[0] == PACKET_EVENT_EXT && len >= 4) {
		body = &packet[4];
		body_len = MIN(sys_get_le16(&packet[2]), len - 4);
	} else {
		LOG_WRN("packet of type 0x%02x", packet[0]);
		return;
	}
	ev.event = packet[1];
	ev.code = 0;
	if (ev.event == BLUENRG_EVENT_LE && body_len >= 1) {
		ev.code = body[0];
		body += 1;
		body_len -= 1;
	} else if (ev.event == BLUENRG_EVENT_VENDOR && body_len >= 2) {
		ev.code = sys_get_le16(body);
		body += 2;
		body_len -= 2;
		if (ev.code == VENDOR_INITIALIZED && starting) {
			/* As asked for: bluenrg_start() waits for this one. */
			starting = false;
			start_reason = body_len >= 1 ? body[0] : 0;
			k_sem_give(&started);
			return;
		}
	}
	ev.len = MIN(body_len, sizeof(ev.data));
	memcpy(ev.data, body, ev.len);
	if (k_msgq_put(&bluenrg_events, &ev, K_MSEC(500)) != 0) {
		LOG_ERR("event 0x%02x 0x%04x lost: nobody takes them", ev.event, ev.code);
	}
}

static void read_thread(void *p1, void *p2, void *p3)
{
	static uint8_t packet[PACKET_MAX];
	int len;

	while (true) {
		k_sem_take(&irq_raised, K_FOREVER);
		while (running && gpio_pin_get_dt(&irq) > 0) {
			len = read_packet(packet, sizeof(packet));
			if (len < 0) {
				LOG_ERR("read: %d", len);
				break;
			}
			if (len >= 2 && !take_answer(packet, len)) {
				queue_event(packet, len);
			}
		}
	}
}
K_THREAD_DEFINE(bluenrg_tid, 2048, read_thread, NULL, NULL, NULL, 6, 0, 0);

int bluenrg_cmd(uint16_t opcode, const void *params, size_t len, void *rsp, size_t rsp_size)
{
	static uint8_t packet[4 + 255];
	int ret;

	if (len > 255) {
		return -EINVAL;
	}
	k_mutex_lock(&cmd_lock, K_FOREVER);
	if (!running) {
		k_mutex_unlock(&cmd_lock);
		return -ENETDOWN;
	}
	packet[0] = PACKET_COMMAND;
	sys_put_le16(opcode, &packet[1]);
	packet[3] = len;
	if (len > 0) {
		memcpy(&packet[4], params, len);
	}
	k_sem_reset(&answered);
	K_SPINLOCK(&pending_lock) {
		pending_opcode = opcode;
		pending = true;
	}
	ret = write_packet(packet, 4 + len);
	if (ret == 0 && k_sem_take(&answered, K_MSEC(ANSWER_MS)) != 0) {
		ret = -ETIMEDOUT;
	}
	K_SPINLOCK(&pending_lock) {
		pending = false;
	}
	if (ret == 0) {
		if (answer_len < 1) {
			ret = -EBADMSG;
		} else {
			ret = answer[0];
			if (rsp != NULL) {
				memcpy(rsp, &answer[1], MIN(rsp_size, answer_len - 1));
			}
		}
	}
	if (ret != 0 && ret != STATUS_NO_BUFFERS) {
		LOG_WRN("command 0x%04x: %s 0x%02x", opcode, ret < 0 ? "error" : "status",
			ret < 0 ? -ret : ret);
	}
	k_mutex_unlock(&cmd_lock);
	return ret;
}

bool bluenrg_event(struct bluenrg_event *event, k_timeout_t timeout)
{
	return k_msgq_get(&bluenrg_events, event, timeout) == 0;
}

void bluenrg_wake(void)
{
	static const struct bluenrg_event wake = {.event = BLUENRG_EVENT_WAKE};

	k_msgq_put(&bluenrg_events, &wake, K_NO_WAIT);
}

int bluenrg_start(void)
{
	static bool set_up;

	if (!set_up) {
		if (!spi_is_ready_dt(&bus) || !gpio_is_ready_dt(&irq) ||
		    !gpio_is_ready_dt(&reset)) {
			return -ENODEV;
		}
		gpio_pin_configure_dt(&irq, GPIO_INPUT);
		gpio_init_callback(&irq_callback, on_irq, BIT(irq.pin));
		gpio_add_callback(irq.port, &irq_callback);
		set_up = true;
	}
	k_mutex_lock(&cmd_lock, K_FOREVER);
	gpio_pin_configure_dt(&reset, GPIO_OUTPUT_ACTIVE);
	k_msleep(RESET_MS);
	k_msgq_purge(&bluenrg_events);
	k_sem_reset(&started);
	running = true;
	starting = true;
	gpio_pin_interrupt_configure_dt(&irq, GPIO_INT_EDGE_TO_ACTIVE);
	gpio_pin_set_dt(&reset, 0);
	k_mutex_unlock(&cmd_lock);

	if (k_sem_take(&started, K_MSEC(START_MS)) != 0) {
		bluenrg_stop();
		return -ETIMEDOUT;
	}
	return 0;
}

uint8_t bluenrg_start_reason(void)
{
	return start_reason;
}

void bluenrg_stop(void)
{
	k_mutex_lock(&cmd_lock, K_FOREVER);
	running = false;
	gpio_pin_interrupt_configure_dt(&irq, GPIO_INT_DISABLE);
	gpio_pin_configure_dt(&reset, GPIO_OUTPUT_ACTIVE);
	k_mutex_unlock(&cmd_lock);
}
```

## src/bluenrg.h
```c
#ifndef UNA_BLUENRG_H_
#define UNA_BLUENRG_H_

#include <stdbool.h>
#include <stddef.h>
#include <stdint.h>

#include <zephyr/kernel.h>

/*
 * The BlueNRG-2N radio chip. It runs the whole Bluetooth stack itself and is
 * told what to do in commands over SPI: HCI's own, and ST's for its GAP and
 * GATT layers (the ACI). What happens comes back as events.
 */

/* Out of reset, and wait until it says it has started. 0 or -errno. */
int bluenrg_start(void);
/*
 * What it said it started as: 1 is the stack, 2 to 4 its updater (asked for,
 * by pin, or because there is no whole stack image), above that after a fault.
 */
uint8_t bluenrg_start_reason(void);
/* Into reset, where it stays and draws nothing. */
void bluenrg_stop(void);

#define BLUENRG_OP(ogf, ocf) ((uint16_t)(((ogf) << 10) | (ocf)))
#define BLUENRG_ACI(ocf)     BLUENRG_OP(0x3f, ocf)

/*
 * Send a command and wait for the chip's answer. Returns the answer's status
 * byte (0 is success, the rest are the chip's error codes) or -errno when
 * there was no answer. What follows the status goes to rsp, as much as fits.
 * Not from the thread that takes the events off bluenrg_event() while it has
 * none to take: any thread else.
 */
int bluenrg_cmd(uint16_t opcode, const void *params, size_t len, void *rsp, size_t rsp_size);

#define BLUENRG_EVENT_MAX 260

enum {
	BLUENRG_EVENT_WAKE = 0x00, /* not the chip's: see bluenrg_wake() */
	BLUENRG_EVENT_DISCONNECTED = 0x05,
	BLUENRG_EVENT_ENCRYPTION = 0x08,
	BLUENRG_EVENT_LE = 0x3e,     /* code is the subevent */
	BLUENRG_EVENT_VENDOR = 0xff, /* code is ST's event code */
};

struct bluenrg_event {
	uint8_t event;
	uint16_t code;
	uint16_t len;
	uint8_t data[BLUENRG_EVENT_MAX]; /* after the subevent or event code */
};

/* The next event; false when none came in time. */
bool bluenrg_event(struct bluenrg_event *event, k_timeout_t timeout);
/* Any thread: have bluenrg_event() return a BLUENRG_EVENT_WAKE. */
void bluenrg_wake(void);

#endif
```
